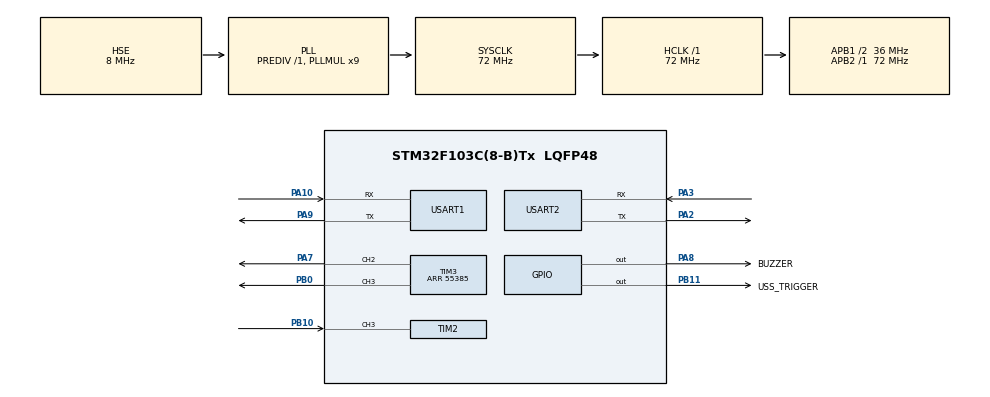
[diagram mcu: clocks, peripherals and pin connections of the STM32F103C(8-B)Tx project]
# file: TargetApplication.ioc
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Mcu.Family=STM32F1
Mcu.Name=STM32F103C(8-B)Tx
Mcu.Package=LQFP48
NVIC.PriorityGroup=NVIC_PRIORITYGROUP_4
NVIC.TIM2_IRQn=true\:2\:0\:true\:false\:true\:true\:true\:true
NVIC.USART1_IRQn=true\:0\:0\:false\:false\:true\:true\:true\:true
PA10.Mode=Asynchronous
PA10.Signal=USART1_RX
PA2.Mode=Asynchronous
PA2.Signal=USART2_TX
PA3.Mode=Asynchronous
PA3.Signal=USART2_RX
PA7.Signal=S_TIM3_CH2
PA8.GPIO_Label=BUZZER
PA8.Signal=GPIO_Output
PA9.Mode=Asynchronous
PA9.Signal=USART1_TX
PB0.Signal=S_TIM3_CH3
PB10.Signal=S_TIM2_CH3
PB11.GPIO_Label=USS_TRIGGER
PB11.Signal=GPIO_Output
PD0-OSC_IN.Mode=HSE-External-Oscillator
PD0-OSC_IN.Signal=RCC_OSC_IN
PD1-OSC_OUT.Mode=HSE-External-Oscillator
PD1-OSC_OUT.Signal=RCC_OSC_OUT
ProjectManager.HeapSize=0x200
ProjectManager.StackSize=0x400
ProjectManager.TargetToolchain=STM32CubeIDE
RCC.AHBFreq_Value=72000000
RCC.APB1CLKDivider=RCC_HCLK_DIV2
RCC.APB1Freq_Value=36000000
RCC.APB1TimFreq_Value=72000000
RCC.APB2Freq_Value=72000000
RCC.APB2TimFreq_Value=72000000
RCC.EnbaleCSS=true
RCC.HCLKFreq_Value=72000000
RCC.PLLMUL=RCC_PLL_MUL9
RCC.PLLSourceVirtual=RCC_PLLSOURCE_HSE
RCC.SYSCLKFreq_VALUE=72000000
RCC.SYSCLKSource=RCC_SYSCLKSOURCE_PLLCLK
RCC.USBFreq_Value=72000000
RTC.Format=RTC_FORMAT_BIN
SH.S_TIM2_CH3.0=TIM2_CH3,Input_Capture3_from_TI3
SH.S_TIM3_CH2.0=TIM3_CH2,PWM Generation2 CH2
SH.S_TIM3_CH3.0=TIM3_CH3,PWM Generation3 CH3
TIM2.Channel-Input_Capture3_from_TI3=TIM_CHANNEL_3
TIM2.Period=0xFFFF-1
TIM2.Prescaler=72-1
TIM3.AutoReloadPreload=TIM_AUTORELOAD_PRELOAD_ENABLE
TIM3.Channel-PWM\ Generation2\ CH2=TIM_CHANNEL_2
TIM3.Channel-PWM\ Generation3\ CH3=TIM_CHANNEL_3
TIM3.OCPolarity_2=TIM_OCPOLARITY_HIGH
TIM3.OCPolarity_3=TIM_OCPOLARITY_HIGH
TIM3.Period=55385
TIM3.Pulse-PWM\ Generation2\ CH2=0
TIM4.Period=0xFFFF-1
TIM4.Prescaler=71
USART1.VirtualMode=VM_ASYNC
USART2.VirtualMode=VM_ASYNC
VP_RTC_No_RTC_Output.Mode=RTC_OUT_NO
VP_RTC_VS_RTC_Activate.Mode=RTC_Enabled
VP_SYS_VS_ND.Mode=No_Debug
VP_TIM3_VS_ClockSourceINT.Mode=Internal
VP_TIM4_VS_ClockSourceINT.Mode=Internal
board=custom

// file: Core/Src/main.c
/* USER CODE BEGIN Header */
/**
  ******************************************************************************
  * @file           : main.c
  * @brief          : Main program body
  ******************************************************************************
  * @attention
  *
  * Copyright (c) 2023 STMicroelectronics.
  * All rights reserved.
  *
  * This software is licensed under terms that can be found in the LICENSE file
  * in the root directory of this software component.
  * If no LICENSE file comes with this software, it is provided AS-IS.
  *
  ******************************************************************************
  */
/* USER CODE END Header */
#include "main.h"
#include "rtc.h"
#include "tim.h"
#include "usart.h"
#include "gpio.h"

/* USER CODE BEGIN Includes */
#include "simple_vehicle_ops.h"

/* USER CODE END Includes */

/* USER CODE BEGIN PM */
void _delay_us(uint16 delay) {
    __HAL_TIM_SET_COUNTER(&htim4, 0);
    while(__HAL_TIM_GET_COUNTER(&htim4) < delay);
}

#define _DELAY_MS(_D) for(uint16 i = 0; i < 1000u; ++i) _delay_us(_D)
/* USER CODE END PM */

void SystemClock_Config(void);

int main(void)
{

  /* MCU Configuration--------------------------------------------------------*/

  /* Reset of all peripherals, Initializes the Flash interface and the Systick. */
  HAL_Init();

  /* Configure the system clock */
  SystemClock_Config();

  /* Initialize all configured peripherals */
  MX_GPIO_Init();
  MX_USART1_UART_Init();
  MX_TIM3_Init();
  MX_USART2_UART_Init();
  MX_TIM4_Init();
  MX_TIM2_Init();
  MX_RTC_Init();
  /* USER CODE BEGIN 2 */
  __disable_irq();

  HAL_TIM_Base_Start(&htim4);
  HAL_TIM_PWM_Start(&htim3, TIM_CHANNEL_2);
  HAL_TIM_PWM_Start(&htim3, TIM_CHANNEL_3);
  HAL_TIM_IC_Start_IT(&htim2, TIM_CHANNEL_3);

  vehicle_init();

  __enable_irq();
  /* USER CODE END 2 */

  /* Infinite loop */
  /* USER CODE BEGIN WHILE */
  while (1)
  {
	  CheckIfDistanceInValidRange(GetUltraSonicDistance());
//	  _DELAY_MS(5);
    /* USER CODE END WHILE */

  }
}

void SystemClock_Config(void)
{
  RCC_OscInitTypeDef RCC_OscInitStruct = {0};
  RCC_ClkInitTypeDef RCC_ClkInitStruct = {0};
  RCC_PeriphCLKInitTypeDef PeriphClkInit = {0};

  /** Initializes the RCC Oscillators according to the specified parameters
  * in the RCC_OscInitTypeDef structure.
  */
  RCC_OscInitStruct.OscillatorType = RCC_OSCILLATORTYPE_LSI|RCC_OSCILLATORTYPE_HSE;
  RCC_OscInitStruct.HSEState = RCC_HSE_ON;
  RCC_OscInitStruct.HSEPredivValue = RCC_HSE_PREDIV_DIV1;
  RCC_OscInitStruct.HSIState = RCC_HSI_ON;
  RCC_OscInitStruct.LSIState = RCC_LSI_ON;
  RCC_OscInitStruct.PLL.PLLState = RCC_PLL_ON;
  RCC_OscInitStruct.PLL.PLLSource = RCC_PLLSOURCE_HSE;
  RCC_OscInitStruct.PLL.PLLMUL = RCC_PLL_MUL9;
  if (HAL_RCC_OscConfig(&RCC_OscInitStruct) != HAL_OK)
  {
    Error_Handler();
  }

  /** Initializes the CPU, AHB and APB buses clocks
  */
  RCC_ClkInitStruct.ClockType = RCC_CLOCKTYPE_HCLK|RCC_CLOCKTYPE_SYSCLK
                              |RCC_CLOCKTYPE_PCLK1|RCC_CLOCKTYPE_PCLK2;
  RCC_ClkInitStruct.SYSCLKSource = RCC_SYSCLKSOURCE_PLLCLK;
  RCC_ClkInitStruct.AHBCLKDivider = RCC_SYSCLK_DIV1;
  RCC_ClkInitStruct.APB1CLKDivider = RCC_HCLK_DIV2;
  RCC_ClkInitStruct.APB2CLKDivider = RCC_HCLK_DIV1;

  if (HAL_RCC_ClockConfig(&RCC_ClkInitStruct, FLASH_LATENCY_2) != HAL_OK)
  {
    Error_Handler();
  }
  PeriphClkInit.PeriphClockSelection = RCC_PERIPHCLK_RTC;
  PeriphClkInit.RTCClockSelection = RCC_RTCCLKSOURCE_LSI;
  if (HAL_RCCEx_PeriphCLKConfig(&PeriphClkInit) != HAL_OK)
  {
    Error_Handler();
  }

  /** Enables the Clock Security System
  */
  HAL_RCC_EnableCSS();
}

void Error_Handler(void)
{
  __disable_irq();
  while (1)
  {
  }
}
